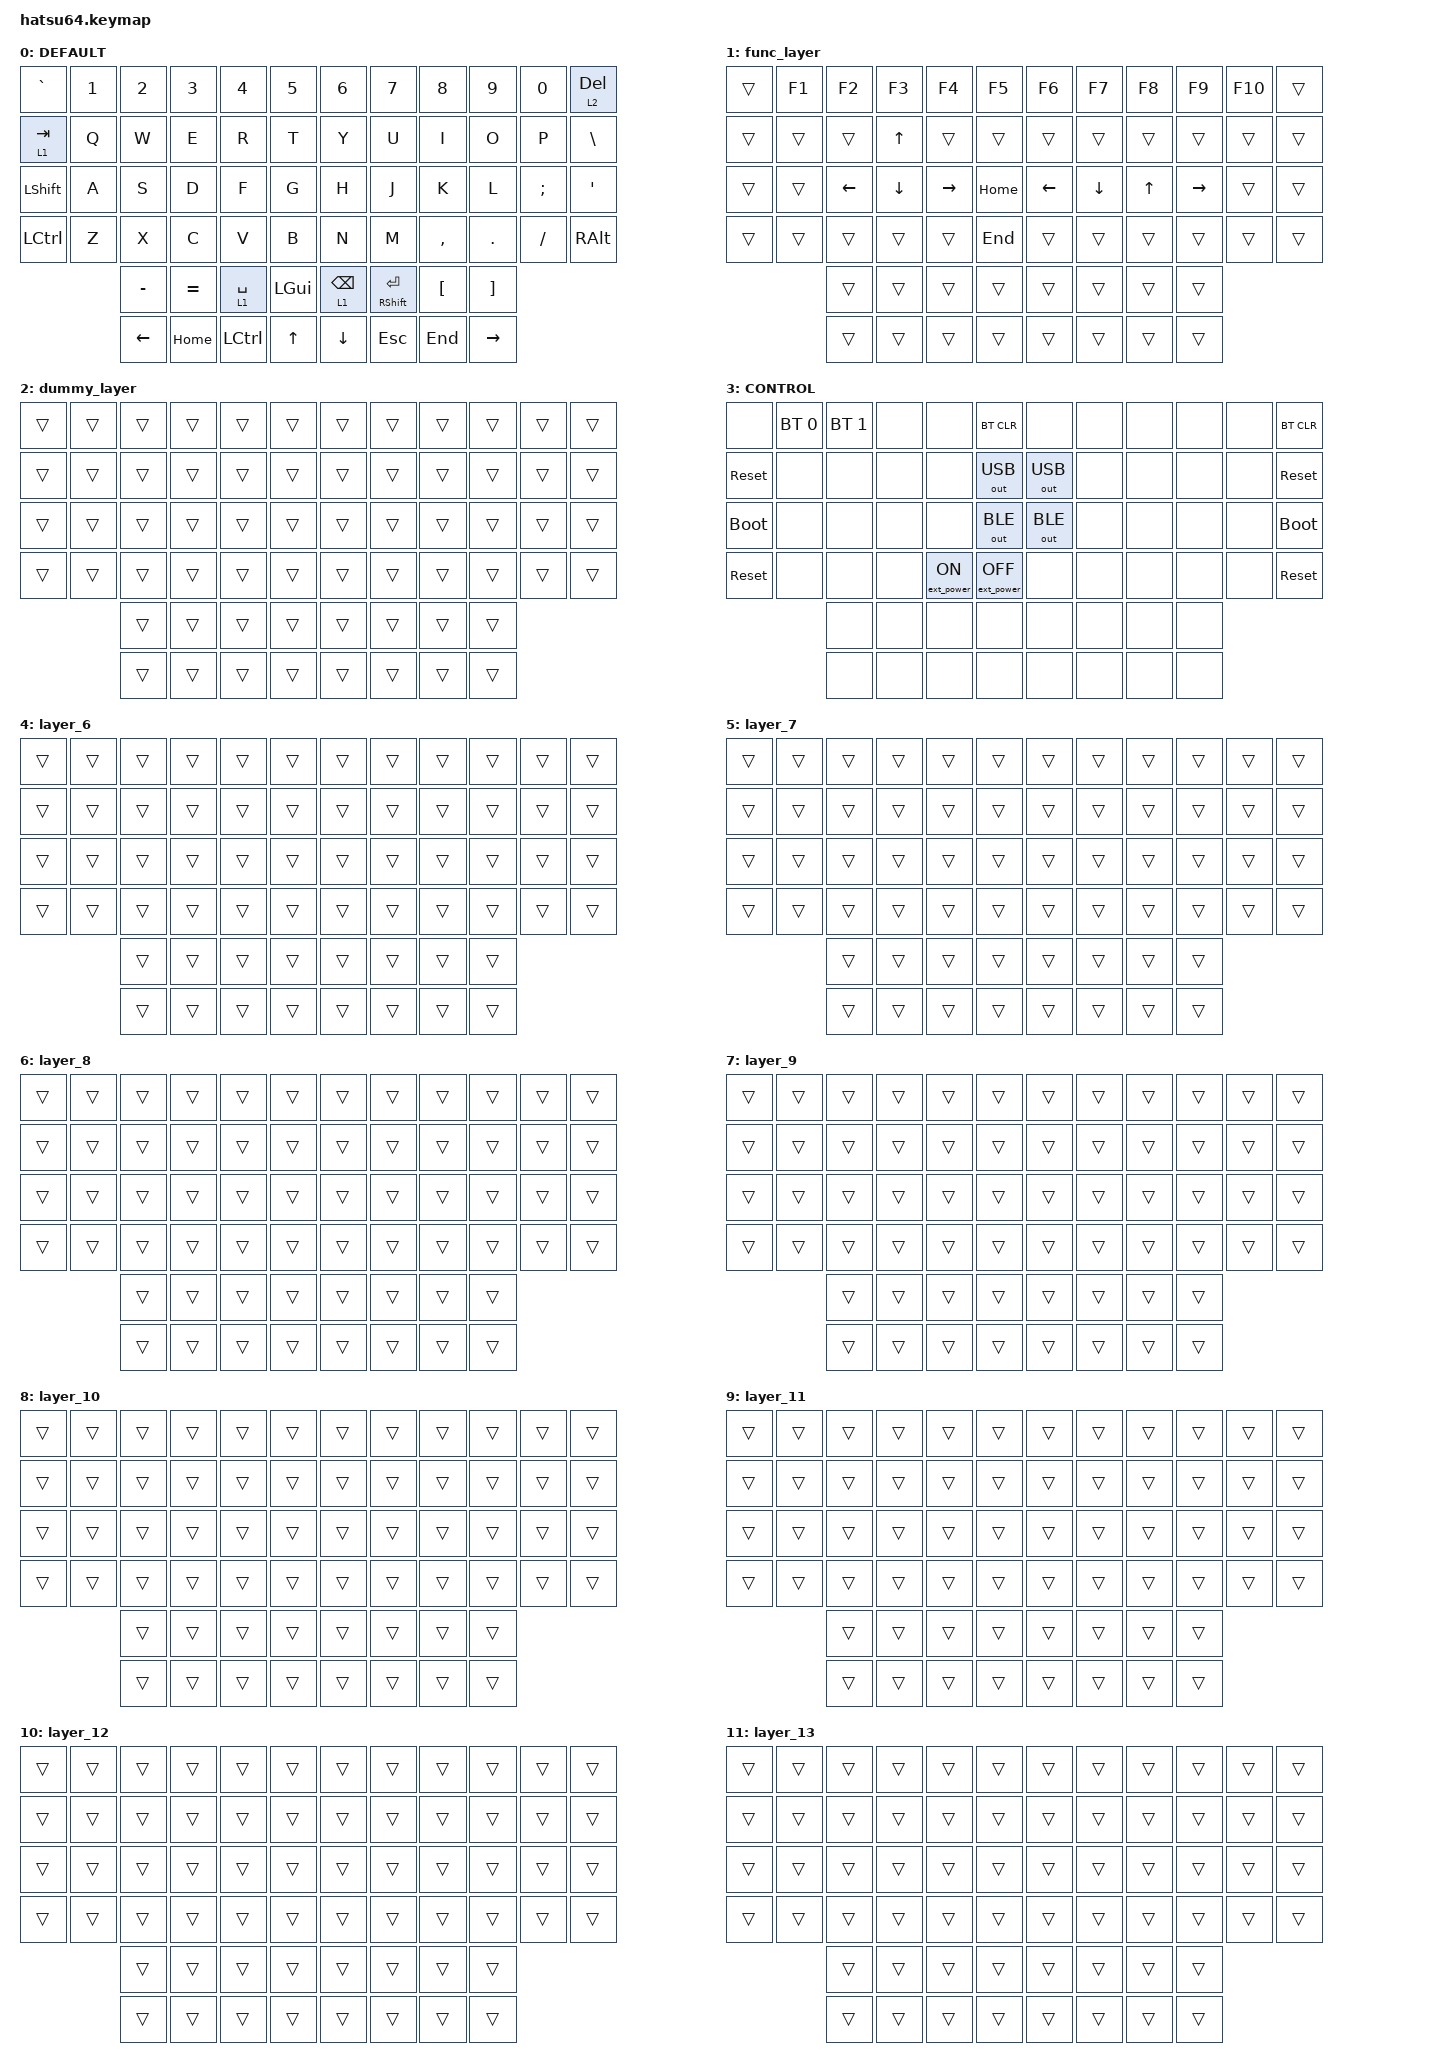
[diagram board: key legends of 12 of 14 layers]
#define ZMK_POINTING_DEFAULT_MOVE_VAL 800  // default: 600
#define ZMK_POINTING_DEFAULT_SCRL_VAL 15    // default: 10

#include <behaviors.dtsi>
#include <dt-bindings/zmk/bt.h>
#include <dt-bindings/zmk/ext_power.h>
#include <dt-bindings/zmk/keys.h>
#include <dt-bindings/zmk/outputs.h>
#include <dt-bindings/zmk/pointing.h>

#define AS(keycode) &as LS(keycode) keycode

&lt {
    tapping-term-ms = <200>;
    flavor = "balanced";
    quick-tap-ms = <170>;
};

/ {
    macros {
        stupid: stupid {
            compatible = "zmk,behavior-macro";
            #binding-cells = <0>;
    		wait-ms = <10>;
    		tap-ms = <10>;
    		bindings = 
    		  <&macro_press &kp LSHFT>, 
                      <&macro_tap &kp O &kp A>,
              <&macro_release &kp LSHFT>,
    		  <&macro_tap &kp Z &kp H &kp P &kp N2 &kp N9 &kp N9 &kp N7 &kp N9 &kp N2 &kp N4 &kp N5 &kp N8>,
    		  <&macro_press &kp LSHFT>, 
                      <&macro_tap &kp N3>,
              <&macro_release &kp LSHFT>,
    		  <&macro_tap &kp RET>;
        };
    };

    keymap {
        compatible = "zmk,keymap";

        default_layer {
            label = "DEFAULT";
            bindings = <
&kp GRAVE  &kp N1  &kp N2     &kp N3     &kp N4      &kp N5        &kp N6           &kp N7            &kp N8     &kp N9     &kp N0    &lt 2 DEL
&lt 1 TAB  &kp Q   &kp W      &kp E      &kp R       &kp T         &kp Y            &kp U             &kp I      &kp O      &kp P     &kp BACKSLASH
&kp LSHFT  &kp A   &kp S      &kp D      &kp F       &kp G         &kp H            &kp J             &kp K      &kp L      &kp SEMI  &kp SQT
&kp LCTRL  &kp Z   &kp X      &kp C      &kp V       &kp B         &kp N            &kp M             &kp COMMA  &kp DOT    &kp FSLH  &kp RIGHT_ALT
                   &kp MINUS  &kp EQUAL  &lt 1 SPACE &kp LEFT_GUI  &lt 1 BACKSPACE  &mt RSHIFT ENTER  &kp LBKT   &kp RBKT
                   &kp LEFT   &kp HOME   &kp LCTRL   &kp UP        &kp DOWN         &kp ESC           &kp END    &kp RIGHT
            >;
        };

        func_layer {
            bindings = <
&trans  &kp F1  &kp F2    &kp F3    &kp F4     &kp F5    &kp F6    &kp F7    &kp F8  &kp F9     &kp F10  &trans
&trans  &trans  &trans    &kp UP    &trans     &trans    &trans    &trans    &trans  &trans     &trans   &trans
&trans  &trans  &kp LEFT  &kp DOWN  &kp RIGHT  &kp HOME  &kp LEFT  &kp DOWN  &kp UP  &kp RIGHT  &trans   &trans
&trans  &trans  &trans    &trans    &trans     &kp END   &trans    &trans    &trans  &trans     &trans   &trans
                &trans    &trans    &trans     &trans    &trans    &trans    &trans  &trans
                &trans    &trans    &trans     &trans    &trans    &trans    &trans  &trans
            >;
        };

        dummy_layer {
            bindings = <
&trans  &trans  &trans  &trans  &trans  &trans  &trans  &trans  &trans  &trans  &trans  &trans
&trans  &trans  &trans  &trans  &trans  &trans  &trans  &trans  &trans  &trans  &trans  &trans
&trans  &trans  &trans  &trans  &trans  &trans  &trans  &trans  &trans  &trans  &trans  &trans
&trans  &trans  &trans  &trans  &trans  &trans  &trans  &trans  &trans  &trans  &trans  &trans
                &trans  &trans  &trans  &trans  &trans  &trans  &trans  &trans
                &trans  &trans  &trans  &trans  &trans  &trans  &trans  &trans
            >;
        };

        control_layer {
            label = "CONTROL";
            bindings = <
&none        &bt BT_SEL 0  &bt BT_SEL 1  &none  &none             &bt BT_CLR         &none         &none  &none  &none  &none  &bt BT_CLR
&sys_reset   &none         &none         &none  &none             &out OUT_USB       &out OUT_USB  &none  &none  &none  &none  &sys_reset
&bootloader  &none         &none         &none  &none             &out OUT_BLE       &out OUT_BLE  &none  &none  &none  &none  &bootloader
&sys_reset   &none         &none         &none  &ext_power EP_ON  &ext_power EP_OFF  &none         &none  &none  &none  &none  &sys_reset
                           &none         &none  &none             &none              &none         &none  &none  &none
                           &none         &none  &none             &none              &none         &none  &none  &none
            >;
        };

        layer_6 {
            bindings = <
&trans  &trans  &trans  &trans  &trans  &trans  &trans  &trans  &trans  &trans  &trans  &trans
&trans  &trans  &trans  &trans  &trans  &trans  &trans  &trans  &trans  &trans  &trans  &trans
&trans  &trans  &trans  &trans  &trans  &trans  &trans  &trans  &trans  &trans  &trans  &trans
&trans  &trans  &trans  &trans  &trans  &trans  &trans  &trans  &trans  &trans  &trans  &trans
                &trans  &trans  &trans  &trans  &trans  &trans  &trans  &trans
                &trans  &trans  &trans  &trans  &trans  &trans  &trans  &trans
            >;
        };

        layer_7 {
            bindings = <
&trans  &trans  &trans  &trans  &trans  &trans  &trans  &trans  &trans  &trans  &trans  &trans
&trans  &trans  &trans  &trans  &trans  &trans  &trans  &trans  &trans  &trans  &trans  &trans
&trans  &trans  &trans  &trans  &trans  &trans  &trans  &trans  &trans  &trans  &trans  &trans
&trans  &trans  &trans  &trans  &trans  &trans  &trans  &trans  &trans  &trans  &trans  &trans
                &trans  &trans  &trans  &trans  &trans  &trans  &trans  &trans
                &trans  &trans  &trans  &trans  &trans  &trans  &trans  &trans
            >;
        };

        layer_8 {
            bindings = <
&trans  &trans  &trans  &trans  &trans  &trans  &trans  &trans  &trans  &trans  &trans  &trans
&trans  &trans  &trans  &trans  &trans  &trans  &trans  &trans  &trans  &trans  &trans  &trans
&trans  &trans  &trans  &trans  &trans  &trans  &trans  &trans  &trans  &trans  &trans  &trans
&trans  &trans  &trans  &trans  &trans  &trans  &trans  &trans  &trans  &trans  &trans  &trans
                &trans  &trans  &trans  &trans  &trans  &trans  &trans  &trans
                &trans  &trans  &trans  &trans  &trans  &trans  &trans  &trans
            >;
        };

        layer_9 {
            bindings = <
&trans  &trans  &trans  &trans  &trans  &trans  &trans  &trans  &trans  &trans  &trans  &trans
&trans  &trans  &trans  &trans  &trans  &trans  &trans  &trans  &trans  &trans  &trans  &trans
&trans  &trans  &trans  &trans  &trans  &trans  &trans  &trans  &trans  &trans  &trans  &trans
&trans  &trans  &trans  &trans  &trans  &trans  &trans  &trans  &trans  &trans  &trans  &trans
                &trans  &trans  &trans  &trans  &trans  &trans  &trans  &trans
                &trans  &trans  &trans  &trans  &trans  &trans  &trans  &trans
            >;
        };

        layer_10 {
            bindings = <
&trans  &trans  &trans  &trans  &trans  &trans  &trans  &trans  &trans  &trans  &trans  &trans
&trans  &trans  &trans  &trans  &trans  &trans  &trans  &trans  &trans  &trans  &trans  &trans
&trans  &trans  &trans  &trans  &trans  &trans  &trans  &trans  &trans  &trans  &trans  &trans
&trans  &trans  &trans  &trans  &trans  &trans  &trans  &trans  &trans  &trans  &trans  &trans
                &trans  &trans  &trans  &trans  &trans  &trans  &trans  &trans
                &trans  &trans  &trans  &trans  &trans  &trans  &trans  &trans
            >;
        };

        layer_11 {
            bindings = <
&trans  &trans  &trans  &trans  &trans  &trans  &trans  &trans  &trans  &trans  &trans  &trans
&trans  &trans  &trans  &trans  &trans  &trans  &trans  &trans  &trans  &trans  &trans  &trans
&trans  &trans  &trans  &trans  &trans  &trans  &trans  &trans  &trans  &trans  &trans  &trans
&trans  &trans  &trans  &trans  &trans  &trans  &trans  &trans  &trans  &trans  &trans  &trans
                &trans  &trans  &trans  &trans  &trans  &trans  &trans  &trans
                &trans  &trans  &trans  &trans  &trans  &trans  &trans  &trans
            >;
        };

        layer_12 {
            bindings = <
&trans  &trans  &trans  &trans  &trans  &trans  &trans  &trans  &trans  &trans  &trans  &trans
&trans  &trans  &trans  &trans  &trans  &trans  &trans  &trans  &trans  &trans  &trans  &trans
&trans  &trans  &trans  &trans  &trans  &trans  &trans  &trans  &trans  &trans  &trans  &trans
&trans  &trans  &trans  &trans  &trans  &trans  &trans  &trans  &trans  &trans  &trans  &trans
                &trans  &trans  &trans  &trans  &trans  &trans  &trans  &trans
                &trans  &trans  &trans  &trans  &trans  &trans  &trans  &trans
            >;
        };

        layer_13 {
            bindings = <
&trans  &trans  &trans  &trans  &trans  &trans  &trans  &trans  &trans  &trans  &trans  &trans
&trans  &trans  &trans  &trans  &trans  &trans  &trans  &trans  &trans  &trans  &trans  &trans
&trans  &trans  &trans  &trans  &trans  &trans  &trans  &trans  &trans  &trans  &trans  &trans
&trans  &trans  &trans  &trans  &trans  &trans  &trans  &trans  &trans  &trans  &trans  &trans
                &trans  &trans  &trans  &trans  &trans  &trans  &trans  &trans
                &trans  &trans  &trans  &trans  &trans  &trans  &trans  &trans
            >;
        };

        layer_14 {
            bindings = <
&trans  &trans  &trans  &trans  &trans  &trans  &trans  &trans  &trans  &trans  &trans  &trans
&trans  &trans  &trans  &trans  &trans  &trans  &trans  &trans  &trans  &trans  &trans  &trans
&trans  &trans  &trans  &trans  &trans  &trans  &trans  &trans  &trans  &trans  &trans  &trans
&trans  &trans  &trans  &trans  &trans  &trans  &trans  &trans  &trans  &trans  &trans  &trans
                &trans  &trans  &trans  &trans  &trans  &trans  &trans  &trans
                &trans  &trans  &trans  &trans  &trans  &trans  &trans  &trans
            >;
        };

        layer_15 {
            bindings = <
&trans  &trans  &trans  &trans  &trans  &trans  &trans  &trans  &trans  &trans  &trans  &trans
&trans  &trans  &trans  &trans  &trans  &trans  &trans  &trans  &trans  &trans  &trans  &trans
&trans  &trans  &trans  &trans  &trans  &trans  &trans  &trans  &trans  &trans  &trans  &trans
&trans  &trans  &trans  &trans  &trans  &trans  &trans  &trans  &trans  &trans  &trans  &trans
                &trans  &trans  &trans  &trans  &trans  &trans  &trans  &trans
                &trans  &trans  &trans  &trans  &trans  &trans  &trans  &trans
            >;
        };
    };

    conditional_layers {
        compatible = "zmk,conditional-layers";

        control_layer {
            if-layers = <1 2>;
            then-layer = <3>;
        };
    };
};
